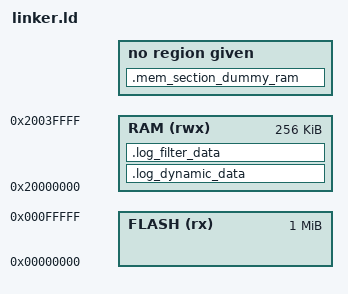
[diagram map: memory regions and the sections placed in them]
/* Linker script for nRF52840 WITHOUT SoftDevice.
 * The butterfly firmware owns the radio bare-metal, so there is no SoftDevice:
 * the application starts at flash origin 0x0 and uses all of RAM.
 * Based on the nRF5 SDK bare-metal (blinky) memory layout. */

SEARCH_DIR(.)
GROUP(-lgcc -lc -lnosys)

MEMORY
{
  FLASH (rx) : ORIGIN = 0x00000000, LENGTH = 0x100000
  RAM (rwx) : ORIGIN = 0x20000000, LENGTH = 0x40000
}

SECTIONS
{
  . = ALIGN(4);
  .mem_section_dummy_ram :
  {
  }
  .log_dynamic_data :
  {
    PROVIDE(__start_log_dynamic_data = .);
    KEEP(*(SORT(.log_dynamic_data*)))
    PROVIDE(__stop_log_dynamic_data = .);
  } > RAM
  .log_filter_data :
  {
    PROVIDE(__start_log_filter_data = .);
    KEEP(*(SORT(.log_filter_data*)))
    PROVIDE(__stop_log_filter_data = .);
  } > RAM

} INSERT AFTER .data;

SECTIONS
{
  .mem_section_dummy_rom :
  {
  }
  .nrf_queue :
  {
    PROVIDE(__start_nrf_queue = .);
    KEEP(*(.nrf_queue))
    PROVIDE(__stop_nrf_queue = .);
  } > FLASH
  .nrf_balloc :
  {
    PROVIDE(__start_nrf_balloc = .);
    KEEP(*(.nrf_balloc))
    PROVIDE(__stop_nrf_balloc = .);
  } > FLASH
  .log_const_data :
  {
    PROVIDE(__start_log_const_data = .);
    KEEP(*(SORT(.log_const_data*)))
    PROVIDE(__stop_log_const_data = .);
  } > FLASH
  .log_backends :
  {
    PROVIDE(__start_log_backends = .);
    KEEP(*(SORT(.log_backends*)))
    PROVIDE(__stop_log_backends = .);
  } > FLASH

} INSERT AFTER .text


INCLUDE "nrf_common.ld"
